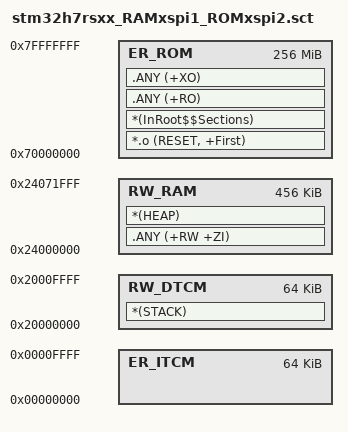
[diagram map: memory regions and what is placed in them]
; *************************************************************
; *** Scatter-Loading Description File generated by uVision ***
; *************************************************************

LOAD_FLASH 0x70000000 0x10000000  {    ; load region size_region
  ER_ROM 0x70000000 0x10000000  {  ; load address = execution address
   *.o (RESET, +First)
   *(InRoot$$Sections)
   .ANY (+RO)
   .ANY (+XO)
  }

  ER_ITCM 0x00000000 0x00010000  {  ;
  }

  RW_DTCM 0x20000000 0x00010000  {  ; RW data
   *(STACK)
  }
  
  RW_RAM 0x24000000  0x00072000  {
   .ANY (+RW +ZI)
   *(HEAP)
  }
}
